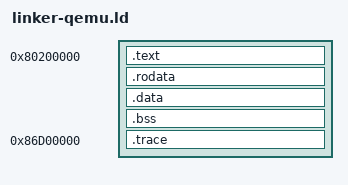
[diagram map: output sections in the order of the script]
OUTPUT_ARCH(riscv)
ENTRY(_start)
BASE_ADDRESS = 0x80200000;

SECTIONS
{
    . = BASE_ADDRESS;
    skernel = .;

    stext = .;
    .text : {
        *(.text.entry)
        . = ALIGN(4K);
        strampoline = .;
        *(.text.trampoline);
        . = ALIGN(4K);
        *(.text .text.*)
    }

    . = ALIGN(4K);
    etext = .;
    srodata = .;
    .rodata : {
        *(.rodata .rodata.*)
        *(.srodata .srodata.*)
    }

    . = ALIGN(4K);
    erodata = .;
    sdata = .;
    .data : {
        *(.data .data.*)
        *(.sdata .sdata.*)
    }

    . = ALIGN(4K);
    edata = .;
    sbss_with_stack = .;
    .bss : {
        *(.bss.stack)
        sbss = .;
        *(.bss .bss.*)
        *(.sbss .sbss.*)
    }

    . = ALIGN(4K);
    ebss = .;
    ekernel = .;

    TRACE_BASE = 0x86d00000;
    TRACE_SIZE = 0x1000000;
    . = TRACE_BASE;
    strace = .;
    .trace (NOLOAD) : {
        KEEP(*(.trace .trace.*))
        . = ALIGN(4K);
    }
    etrace = .;
    ASSERT(etrace - strace <= TRACE_SIZE, "trace section exceeds reserved RAM area")

    /DISCARD/ : {
        *(.eh_frame)
    }
}
